# pwm_wrap: IP-XACT component
VLNV tenstorrent.com:ocah:pwm_wrap:1.0

## Address spaces and blocks
pwm_wrap.pwm: base 'h0, range 'h44, width 32
pwm_wrap.pwm_ctrl: base 'h800, range 'h4, width 32

## Registers
Registers are 32-bit, read-write, reset 0x0 unless marked. A register's access mark holds for its fields unless they carry their own. Offsets are from the block's base; lines under a group give offsets from that group; [hi:lo] are bit positions; {n}, {i} and the like mark numbered series; 'fields as' and 'values as' point back to an identical list; <NAME> marks a mode.

## pwm_wrap.pwm — Transmission of pulse-width modulated output signals with adjustable duty cycle
Base 0x00000000
0x00 ALERT_TEST wo
  [0] fatal_fault — Write 1 to trigger one alert event of this kind.
0x04 REGWEN reset 0x1
  [0] REGWEN write-0-clears — When true, all writable registers can be modified. When false, they become read-only. Defaults true, write zero to clear. This can be cleared after initial configuration at boot in order to lock in the supplied register settings.
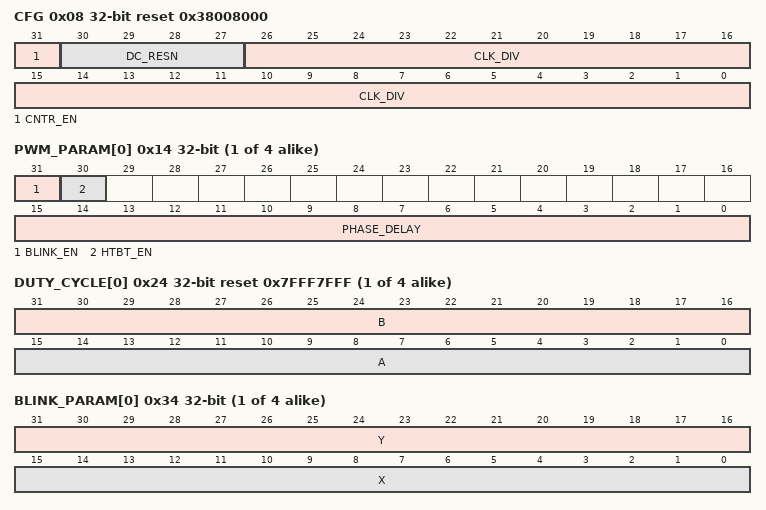
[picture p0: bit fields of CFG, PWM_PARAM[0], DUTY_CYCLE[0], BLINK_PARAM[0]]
0x08 CFG reset 0x38008000
  [31] CNTR_EN — Assert this bit to enable the PWM phase counter. Clearing this bit disables and resets the phase counter.
  [30:27] DC_RESN — Phase Resolution (logarithmic). All duty-cycle and phase shift registers represent fractional PWM cycles, expressed in units of 2^-16 PWM cycles. Each PWM cycle is divided into 2^(DC_RESN+1) time slices, and thus only the (DC_RESN+1) most significant bits of each phase or duty cycle register are relevant.
  [26:0] CLK_DIV — Sets the period of each PWM beat to be (CLK_DIV+1) input clock periods. Since PWM pulses are generated once every 2^(DC_RESN+1) beats, the period between output pulses is 2^(DC_RESN+1)*(CLK_DIV+1) times longer than the input clock period.
0x0C PWM_EN
  [3:0] EN — Write 1 to this bit to enable PWM pulses on the corresponding channel.
0x10 INVERT
  [3:0] INVERT — Write 1 to this bit to invert the output for each channel, so that the corresponding output is active-low.
{0x14+4i} PWM_PARAM[{i}] (i=0..3)
  [31] BLINK_EN — Enables blink (or heartbeat). If cleared, the output duty cycle will remain constant at DUTY_CYCLE.A. Enabling this bit causes the PWM duty cycle to alternate between DUTY_CYCLE.A and DUTY_CYCLE.B
  [30] HTBT_EN — Modulates blink behavior to create a heartbeat effect. When HTBT_EN is set, the duty cycle increases (or decreases) linearly from DUTY_CYCLE.A to DUTY_CYCLE.B and back, in steps of (BLINK_PARAM.Y+1), with an increment (decrement) once every (BLINK_PARAM.X+1) PWM cycles. When HTBT_EN is cleared, the standard blink behavior applies, meaning that the output duty cycle alternates between DUTY_CYCLE.A for (BLINK_PARAM.X+1) pulses and DUTY_CYCLE.B for (BLINK_PARAM.Y+1) pulses.
  [15:0] PHASE_DELAY — Phase delay of the PWM leading edge, in units of 2^(-16) PWM cycles. The leading edge will be the rising edge of the output signal unless the corresponding INVERT bit is set.
{0x24+4i} DUTY_CYCLE[{i}] (i=0..3) reset 0x7FFF7FFF
  [31:16] B — The target duty cycle for PWM output, in units of 2^(-16)ths of a pulse cycle. The actual precision is however limited to the (DC_RESN+1) most significant bits. This setting only applies when blinking, and determines the target duty cycle.
  [15:0] A — The initial duty cycle for PWM output, in units of 2^(-16)ths of a pulse cycle. The actual precision is however limited to the (DC_RESN+1) most significant bits. This setting applies continuously when not blinking and determines the initial duty cycle when blinking.
{0x34+4i} BLINK_PARAM[{i}] (i=0..3)
  [31:16] Y — This blink-rate timing parameter has two different interpretations depending on whether or not the heartbeat feature is enabled. If heartbeat is disabled, a blinking PWM will pulse at duty cycle B for (Y+1) pulse cycles before returning to duty cycle A. If heartbeat is enabled the duty cycle will increase (or decrease) by (Y+1) units every time it is incremented (or decremented).
  [15:0] X — This blink-rate timing parameter has two different interpretations depending on whether or not the heartbeat feature is enabled. If heartbeat is disabled, a blinking PWM will pulse at duty cycle A for (X+1) pulse cycles before switching to duty cycle B. If heartbeat is enabled the duty cycle will start at duty cycle A, but will be incremented (or decremented) every (X+1) cycles. In heartbeat mode is enabled, the size of each step is controlled by BLINK_PARAM.Y.

## pwm_wrap.pwm_ctrl — Per-channel pad-function select for the PWM outputs.
Base 0x00000800
0x00 CTRL — Control Register
  [3:0] PAD_EN — PWM Pad Function Select, one bit per channel. When bit i is set, the integration routes channel i's output to its pad. Does not start the channel; PWM_EN starts and stops each channel's waveform.

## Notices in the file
SPDX-License-Identifier: Apache-2.0
SPDX-FileCopyrightText: 2026 Tenstorrent USA, Inc.
